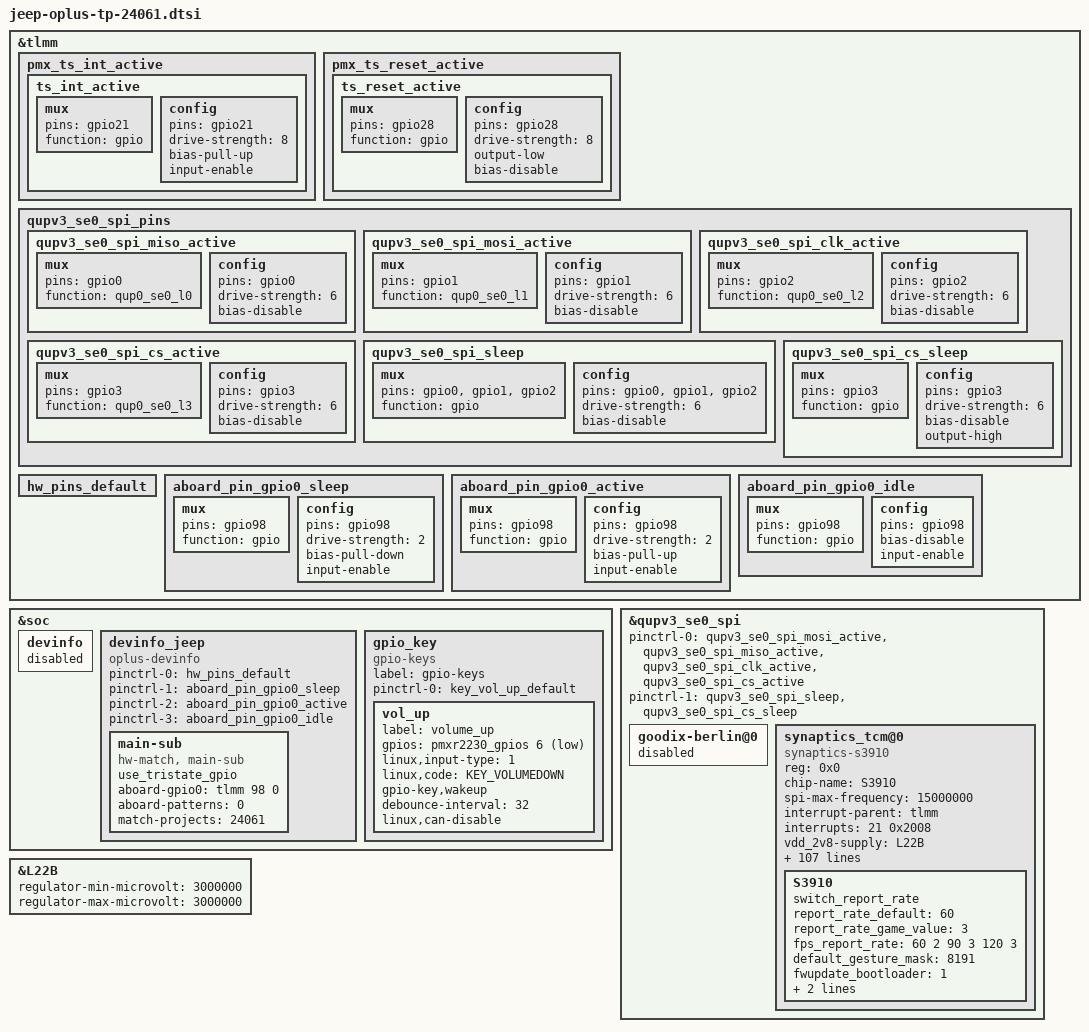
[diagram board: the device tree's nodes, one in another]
&tlmm {
	pmx_ts_int_active {
		ts_int_active: ts_int_active {
			mux {
				pins = "gpio21";
				function = "gpio";
			};

			config {
				pins = "gpio21";
				drive-strength = <8>;
				bias-pull-up;
				input-enable;
			};
		};
	};

	pmx_ts_reset_active {
		ts_reset_active: ts_reset_active {
			mux {
				pins = "gpio28";
				function = "gpio";
			};

			config {
				pins = "gpio28";
				drive-strength = <8>;
				output-low;
				bias-disable;
			};
		};
	};

	qupv3_se0_spi_pins: qupv3_se0_spi_pins {
		qupv3_se0_spi_miso_active: qupv3_se0_spi_miso_active {
			mux {
				pins = "gpio0";
				function = "qup0_se0_l0";
			};

			config {
				pins = "gpio0";
				drive-strength = <6>;
				bias-disable;
			};
		};

		qupv3_se0_spi_mosi_active: qupv3_se0_spi_mosi_active {
			mux {
				pins = "gpio1";
				function = "qup0_se0_l1";
			};

			config {
				pins = "gpio1";
				drive-strength = <6>;
				bias-disable;
			};
		};

		qupv3_se0_spi_clk_active: qupv3_se0_spi_clk_active {
			mux {
				pins = "gpio2";
				function = "qup0_se0_l2";
			};

			config {
				pins = "gpio2";
				drive-strength = <6>;
				bias-disable;
			};
		};

		qupv3_se0_spi_cs_active: qupv3_se0_spi_cs_active {
			mux {
				pins = "gpio3";
				function = "qup0_se0_l3";
			};

			config {
				pins = "gpio3";
				drive-strength = <6>;
				bias-disable;
			};
		};

		qupv3_se0_spi_sleep: qupv3_se0_spi_sleep {
			mux {
				pins = "gpio0", "gpio1",
						"gpio2";
				function = "gpio";
			};

			config {
				pins = "gpio0", "gpio1",
						"gpio2";
				drive-strength = <6>;
				bias-disable;
			};
		};

		qupv3_se0_spi_cs_sleep: qupv3_se0_spi_cs_sleep {
			mux {
				pins = "gpio3";
				function = "gpio";
			};

			config {
				pins = "gpio3";
				drive-strength = <6>;
				bias-disable;
				output-high;
			};
		};
	};

	hw_pins_default:hw_pins_default {
	};
	aboard_pin_gpio0_sleep:aboard_pin_gpio0_sleep {
		mux {
			pins = "gpio98";
			function = "gpio";
		};
		config {
			pins = "gpio98";
			drive-strength = <2>;
			bias-pull-down;
			input-enable;
		};
	};

	aboard_pin_gpio0_active:aboard_pin_gpio0_active {
		mux {
			pins = "gpio98";
			function = "gpio";
		};
		config {
			pins = "gpio98";
			drive-strength = <2>;
			bias-pull-up;
			input-enable;
		};
	};

	aboard_pin_gpio0_idle:aboard_pin_gpio0_idle {
		mux {
			pins = "gpio98";
			function = "gpio";
		};
		config {
			pins = "gpio98";
			bias-disable;
			input-enable;
		};
	};
};

&soc {
	devinfo {
		status = "disabled";
	};

	devinfo_jeep {
		compatible = "oplus-devinfo";

		pinctrl-names = "default", "sleep", "active", "idle";
		pinctrl-0 = <&hw_pins_default>;
		pinctrl-1 = <&aboard_pin_gpio0_sleep>;
		pinctrl-2 = <&aboard_pin_gpio0_active>;
		pinctrl-3 = <&aboard_pin_gpio0_idle>;

		main-sub {
			compatible = "hw-match, main-sub";
			use_tristate_gpio;
			aboard-gpio0 = <&tlmm 98 0>;
			aboard-patterns = <0>;	/*0[high-resistance] 1[pull-down] 2[pull-up]*/
			/*main board*/
			match-projects = <24061>;
		};
	};
};

&qupv3_se0_spi{
	/delete-property/ pinctrl-0;
	/delete-property/ pinctrl-1;
	pinctrl-0 = <&qupv3_se0_spi_mosi_active>, <&qupv3_se0_spi_miso_active>,
				<&qupv3_se0_spi_clk_active>, <&qupv3_se0_spi_cs_active>;
	pinctrl-1 = <&qupv3_se0_spi_sleep>, <&qupv3_se0_spi_cs_sleep>;
};

&qupv3_se0_spi {
	status = "ok";

	goodix-berlin@0 {
		status = "disabled";
	};

	synaptics_tcm@0{
		compatible = "synaptics-s3910";
		reg = <0x0>;
		chip-name = "S3910";
		status = "ok";
		spi-max-frequency = <15000000>;

		/* Interrupt && Irq-gpio */
		interrupt-parent = <&tlmm>;
		interrupts = <21 0x2008>;

		/* Power Config */
		vdd_2v8-supply = <&L22B>;
		vdd_2v8_volt = <3000000>;
		vcc_1v8-supply = <&L8B>;
		vcc_1v8_volt = <1800000>;

		/* Other HW Resource */
		irq-gpio = <&tlmm 21 0x2008>;
		reset-gpio = <&tlmm 28 0x1>;
		pinctrl-names = "default";
		pinctrl-0 = <&ts_int_active &ts_reset_active>;

		touchpanel,max-num-support = <10>;
		touchpanel,tx-rx-num = <16 36>;
		touchpanel,panel-coords = <10800 24120>;
		touchpanel,display-coords = <1080 2412>;
		touchpanel,touchmajor-limit = <256 256>;
		touchpanel,int-mode = <1>; /*0: interrupt and disable, 1:interrupt and not disable*/
		touchpanel,curved-size = <45>;

		prevention,curved_screen_V2;
		prevention,grip_disable_level = <6>;
		prevention,updelay_time_ms = <20>;
		prevention,makeup_cnt_weight = <4 1 2 2 2>;
		prevention,large_corner_range = <1200 3000>;
		prevention,large_corner_judge_condition = <500 300 1000 6 6>;
		prevention,trx_reject_condition = <9 7 7>;
		prevention,trx_strict_reject_condition = <8 6 6>;
		prevention,large_judge_time_ms = <500 50 30>;
		prevention,large_exit_condition = <8 8 2>;
		prevention,single_channel_width = <320 320>;
		prevention,normal_tap_condition = <10 300>;
		prevention,long_edge_condition = <200 90 180 80>;
		prevention,long_strict_edge_condition = <160 60>;
		prevention,long_fingerhold_condition = <50 6 4 4>;
		prevention,short_edge_condition = <200 90 180 80>;
		prevention,short_strict_edge_condition = <160 60>;
		prevention,large_strict_exit_condition = <4 4>;
		prevention,top_corner_config = <500 1500 480>;
		prevention,edge_swipe_config = <300 1200>;

		prevention,curved_screen_V4;
		prevention,long_eliminate_point_type = <2 10800 7236 400 24120 300 1>;
		prevention,long_fingerhold_condition2 = <700 2000 0 0>;
		prevention,top_corner_config2 =<3 80 420 1500 0>;
		prevention,hor_long_top_corner_config =<300 2000 0 0>;
		prevention,top_middle_config =<10800 1000 1000 0>;
		prevention,corner_eliminate_point_type =<0 1200 2000 1>;
		prevention,finger_hold_differ_size = <1 0 300 300>;
		prevention,finger_hold_max_rx_exit_distance = <5 300 2000>;
		prevention,max_rx_exit_distance = <1 5 150 300 2000>;
		prevention,dynamic_finger_hold_exit_distance = <1 300 2000 450>;
		prevention,edge_sliding_matched_support = <1 220 3 0>;

		//grip v4.2 reclining mode
		prevention,reclining_mode_support = <1>;
		prevention,long_eliminate_point_type_recli = <2 10800 7236 500 24120 300 1>;
		prevention,finger_hold_differ_size_recli = <1 0 300 300>;
		prevention,finger_hold_max_rx_exit_distance_recli = <5 300 2000>;
		prevention,max_rx_exit_distance_recli = <1 5 150 300 2000>;
		prevention,dynamic_finger_hold_exit_distance_recli = <1 300 2000 450>;
		prevention,edge_sliding_matched_support_recli = <1 220 3 0>;
		prevention,long_edge_condition_recli = <200 90 180 80>;

		touchpanel,smooth-level = <0 1 2 4 7 9>;
		touchpanel,smooth-level-charging = <0 2 4 7 8 9>;
		touchpanel,sensitive-level = <0 70 55 40 25 10>;
		touchpanel,single-optimized-time = <8>;
		touchpanel,high-frame-rate-time = <60>;

		//touchpanel,tp_ic_type = <2>;
		panel_type = <7>;
		// type of tp_dev ,TP-SAMSUNG = 8;
		//firmware_name = "AC147", "AC147";
		platform_support_project = <24061>;
		platform_support_project_dir = <24061>;
		platform_support_project_commandline = "default_commandline";

		/* SW Support Feature Control */
		black_gesture_support;
		pressure_report_support;
		charger_pump_support;
		game_switch_support;
		smart_gesture_support;
		fw_update_app_support;
		fingerprint_underscreen_support;
		freq_hop_simulate_support;
		report_flow_unlock_support;
		screenoff_fingerprint_info_support;
		irq_need_dev_resume_ok;
		//firmware_in_dts;
		enable_point_auto_change;
		report_rate_white_list_support;
		kernel_grip_support;
		//grip_no_driver_support;
		health_monitor_support;
		black_gesture_indep_support;
		//algorithm_support;
		//spi_port_support;
		exception_upload_support;
		sportify_aod_gesture_support;
		glove_mode_support;
		fingerprint_not_report_in_suspend;
		tp_data_record_support;
		snr_read_support;
		palm_to_sleep_support;
		waterproof_support;

		/*
		 *Virtual Key Config:
		 *1:touchpanel,button-type: <virtualkey_type  supportted_button-map>
		 *virtualkey_type:
		 *Type 1: using board_properties
		 *Type 2: using same IC (button zone&& touch zone are seprate)
		 *Type 3: using diffrent IC (button zone&& touch zone are seprate)
		 *Type 4: No need of virtual key process
		 *supportted_button-map:select|menu|home|back
		 *
		 *2:touchpanel,button-map
		 *type (X1,Y1)(X2,Y2)(X3,Y3)(Width_X,Hight_Y)--Only when button-type is 0
		 */
		touchpanel,button-type = <4>;
		touchpanel.button-TRx = <0 0>;

		S3910 {
			switch_report_rate;
			report_rate_default = <60>;
			report_rate_game_value = <3>;
			fps_report_rate = <60 2 90 3 120 3>;//1:360Hz 2:125Hz 3:240Hz
			default_gesture_mask = <8191>;
			fwupdate_bootloader = <1>;
			normal_config_version = <2>;
			tp_data_record_support;
		};
	};
};

&soc {
	/delete-node/ gpio_key;
	gpio_key {
		compatible = "gpio-keys";
		label = "gpio-keys";
		pinctrl-names = "default";
		pinctrl-0 = <&key_vol_up_default>;
		vol_up {
			label = "volume_up";
			gpios = <&pmxr2230_gpios 6 GPIO_ACTIVE_LOW>;
			linux,input-type = <1>;
			linux,code = <KEY_VOLUMEDOWN>;
			gpio-key,wakeup;
			debounce-interval = <32>;
			linux,can-disable;
		};
	};
};

&L22B {
	/delete-property/ regulator-min-microvolt;
	/delete-property/ regulator-max-microvolt;
	regulator-min-microvolt = <3000000>;
	regulator-max-microvolt = <3000000>;
};
